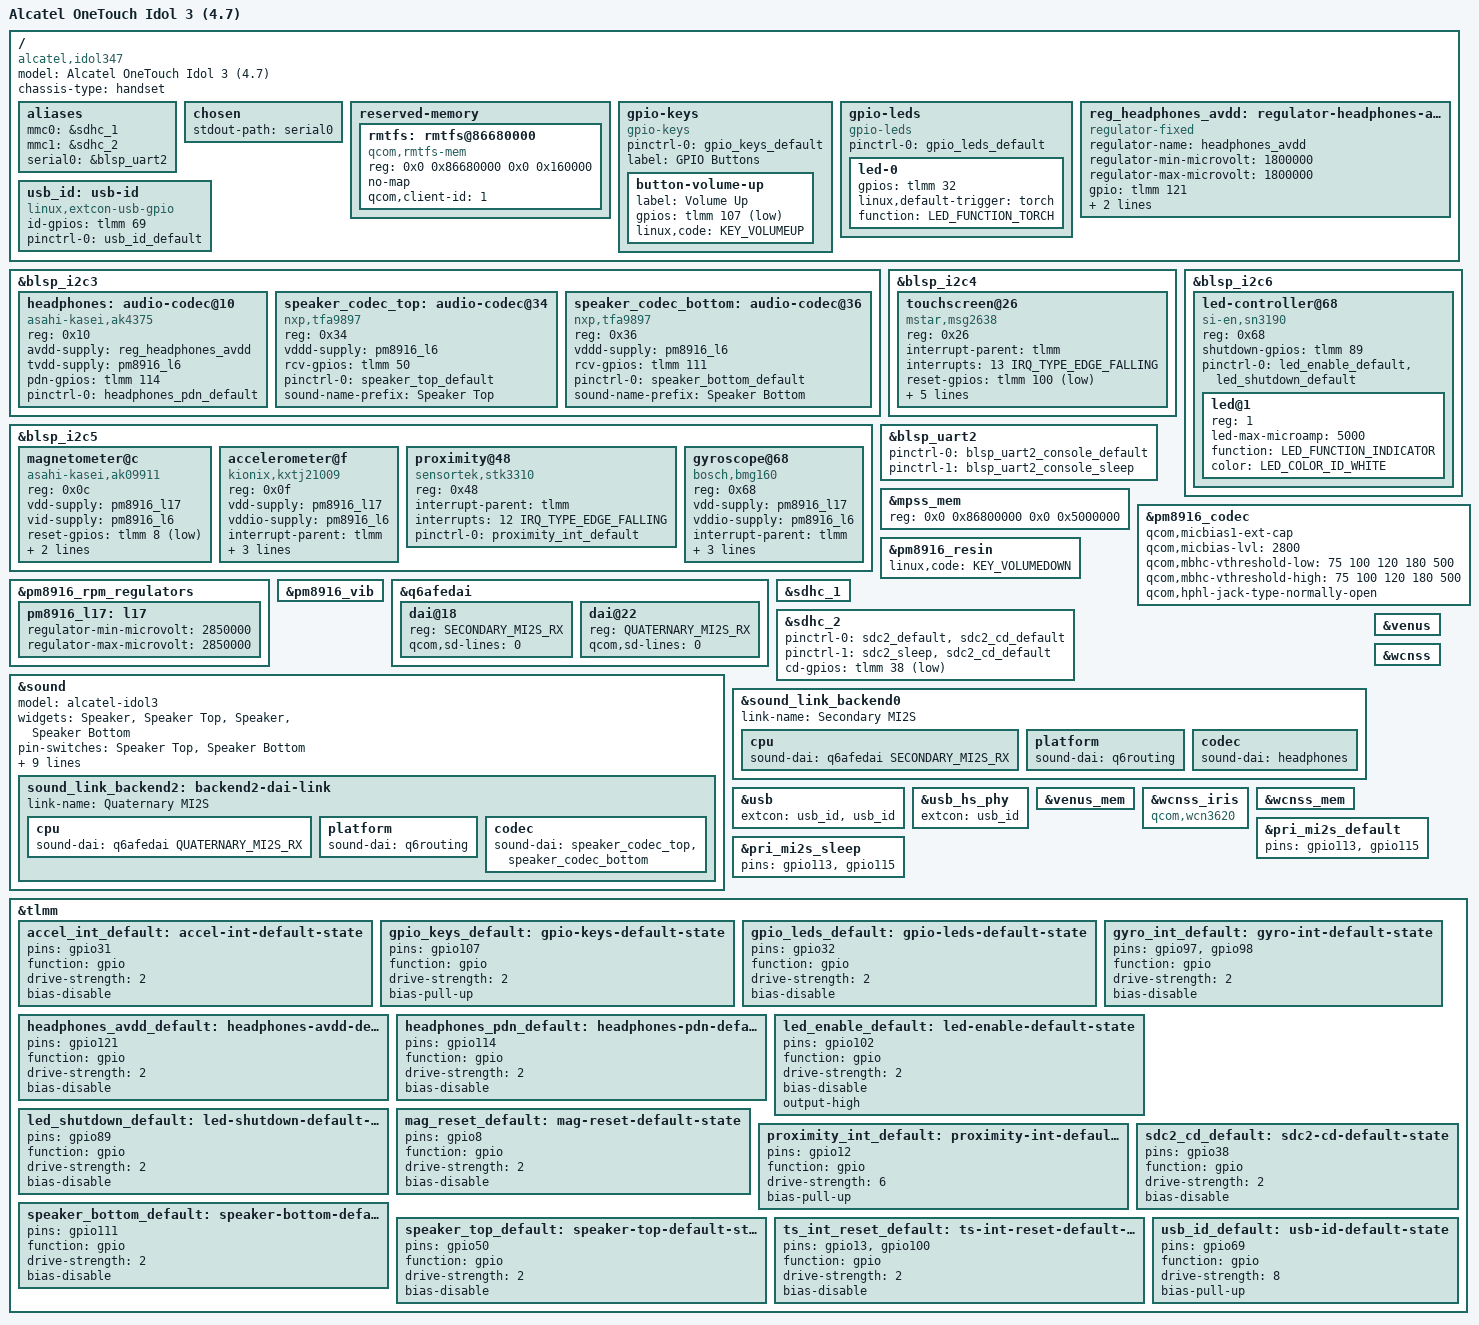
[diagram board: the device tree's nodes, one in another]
// SPDX-License-Identifier: GPL-2.0-only

/dts-v1/;

#include "msm8916-pm8916.dtsi"
#include "msm8916-modem-qdsp6.dtsi"

#include <dt-bindings/gpio/gpio.h>
#include <dt-bindings/input/input.h>
#include <dt-bindings/leds/common.h>

/ {
	model = "Alcatel OneTouch Idol 3 (4.7)";
	compatible = "alcatel,idol347", "qcom,msm8916";
	chassis-type = "handset";

	aliases {
		mmc0 = &sdhc_1; /* eMMC */
		mmc1 = &sdhc_2; /* SD card */
		serial0 = &blsp_uart2;
	};

	chosen {
		stdout-path = "serial0";
	};

	reserved-memory {
		/delete-node/ reserved@86680000;
		/delete-node/ rmtfs@86700000;

		rmtfs: rmtfs@86680000 {
			compatible = "qcom,rmtfs-mem";
			reg = <0x0 0x86680000 0x0 0x160000>;
			no-map;

			qcom,client-id = <1>;
		};
	};

	gpio-keys {
		compatible = "gpio-keys";

		pinctrl-names = "default";
		pinctrl-0 = <&gpio_keys_default>;

		label = "GPIO Buttons";

		button-volume-up {
			label = "Volume Up";
			gpios = <&tlmm 107 GPIO_ACTIVE_LOW>;
			linux,code = <KEY_VOLUMEUP>;
		};
	};

	gpio-leds {
		compatible = "gpio-leds";

		pinctrl-names = "default";
		pinctrl-0 = <&gpio_leds_default>;

		led-0 {
			gpios = <&tlmm 32 GPIO_ACTIVE_HIGH>;
			linux,default-trigger = "torch";
			function = LED_FUNCTION_TORCH;
		};
	};

	reg_headphones_avdd: regulator-headphones-avdd {
		compatible = "regulator-fixed";
		regulator-name = "headphones_avdd";
		regulator-min-microvolt = <1800000>;
		regulator-max-microvolt = <1800000>;
		gpio = <&tlmm 121 GPIO_ACTIVE_HIGH>;
		enable-active-high;
		pinctrl-0 = <&headphones_avdd_default>;
		pinctrl-names = "default";
	};

	usb_id: usb-id {
		compatible = "linux,extcon-usb-gpio";
		id-gpios = <&tlmm 69 GPIO_ACTIVE_HIGH>;
		pinctrl-names = "default";
		pinctrl-0 = <&usb_id_default>;
	};
};

&blsp_i2c3 {
	status = "okay";

	headphones: audio-codec@10 {
		compatible = "asahi-kasei,ak4375";
		reg = <0x10>;
		avdd-supply = <&reg_headphones_avdd>;
		tvdd-supply = <&pm8916_l6>;
		pdn-gpios = <&tlmm 114 GPIO_ACTIVE_HIGH>;
		pinctrl-0 = <&headphones_pdn_default>;
		pinctrl-names = "default";
		#sound-dai-cells = <0>;
	};

	speaker_codec_top: audio-codec@34 {
		compatible = "nxp,tfa9897";
		reg = <0x34>;
		vddd-supply = <&pm8916_l6>;
		rcv-gpios = <&tlmm 50 GPIO_ACTIVE_HIGH>;
		pinctrl-0 = <&speaker_top_default>;
		pinctrl-names = "default";
		sound-name-prefix = "Speaker Top";
		#sound-dai-cells = <0>;
	};

	speaker_codec_bottom: audio-codec@36 {
		compatible = "nxp,tfa9897";
		reg = <0x36>;
		vddd-supply = <&pm8916_l6>;
		rcv-gpios = <&tlmm 111 GPIO_ACTIVE_HIGH>;
		pinctrl-0 = <&speaker_bottom_default>;
		pinctrl-names = "default";
		sound-name-prefix = "Speaker Bottom";
		#sound-dai-cells = <0>;
	};
};

&blsp_i2c4 {
	status = "okay";

	touchscreen@26 {
		compatible = "mstar,msg2638";
		reg = <0x26>;
		interrupt-parent = <&tlmm>;
		interrupts = <13 IRQ_TYPE_EDGE_FALLING>;
		reset-gpios = <&tlmm 100 GPIO_ACTIVE_LOW>;
		pinctrl-names = "default";
		pinctrl-0 = <&ts_int_reset_default>;
		vdd-supply = <&pm8916_l17>;
		vddio-supply = <&pm8916_l5>;
		touchscreen-size-x = <2048>;
		touchscreen-size-y = <2048>;
	};
};

&blsp_i2c5 {
	status = "okay";

	magnetometer@c {
		compatible = "asahi-kasei,ak09911";
		reg = <0x0c>;
		vdd-supply = <&pm8916_l17>;
		vid-supply = <&pm8916_l6>;
		reset-gpios = <&tlmm 8 GPIO_ACTIVE_LOW>;
		pinctrl-names = "default";
		pinctrl-0 = <&mag_reset_default>;
		mount-matrix = "0", "1", "0",
			       "-1", "0", "0",
			       "0", "0", "1";
	};

	accelerometer@f {
		compatible = "kionix,kxtj21009";
		reg = <0x0f>;
		vdd-supply = <&pm8916_l17>;
		vddio-supply = <&pm8916_l6>;
		interrupt-parent = <&tlmm>;
		interrupts = <31 IRQ_TYPE_EDGE_RISING>;
		pinctrl-names = "default";
		pinctrl-0 = <&accel_int_default>;
		mount-matrix = "-1", "0", "0",
			       "0", "1", "0",
			       "0", "0", "-1";
	};

	proximity@48 {
		compatible = "sensortek,stk3310";
		reg = <0x48>;
		interrupt-parent = <&tlmm>;
		interrupts = <12 IRQ_TYPE_EDGE_FALLING>;
		pinctrl-names = "default";
		pinctrl-0 = <&proximity_int_default>;
	};

	gyroscope@68 {
		compatible = "bosch,bmg160";
		reg = <0x68>;
		vdd-supply = <&pm8916_l17>;
		vddio-supply = <&pm8916_l6>;
		interrupt-parent = <&tlmm>;
		interrupts = <97 IRQ_TYPE_EDGE_RISING>,
			     <98 IRQ_TYPE_EDGE_RISING>;
		pinctrl-names = "default";
		pinctrl-0 = <&gyro_int_default>;
	};
};

&blsp_i2c6 {
	status = "okay";

	led-controller@68 {
		compatible = "si-en,sn3190";
		reg = <0x68>;
		shutdown-gpios = <&tlmm 89 GPIO_ACTIVE_HIGH>;
		pinctrl-names = "default";
		pinctrl-0 = <&led_enable_default &led_shutdown_default>;
		#address-cells = <1>;
		#size-cells = <0>;

		led@1 {
			reg = <1>;
			led-max-microamp = <5000>;
			function = LED_FUNCTION_INDICATOR;
			color = <LED_COLOR_ID_WHITE>;
		};
	};
};

&blsp_uart2 {
	status = "okay";
	pinctrl-0 = <&blsp_uart2_console_default>;
	pinctrl-1 = <&blsp_uart2_console_sleep>;
	pinctrl-names = "default", "sleep";
};

&mpss_mem {
	reg = <0x0 0x86800000 0x0 0x5000000>;
};

&pm8916_codec {
	qcom,micbias1-ext-cap;
	qcom,micbias-lvl = <2800>;
	qcom,mbhc-vthreshold-low = <75 100 120 180 500>;
	qcom,mbhc-vthreshold-high = <75 100 120 180 500>;
	qcom,hphl-jack-type-normally-open;
};

&pm8916_resin {
	status = "okay";
	linux,code = <KEY_VOLUMEDOWN>;
};

&pm8916_rpm_regulators {
	pm8916_l17: l17 {
		regulator-min-microvolt = <2850000>;
		regulator-max-microvolt = <2850000>;
	};
};

&pm8916_vib {
	status = "okay";
};

&q6afedai {
	dai@18 {
		reg = <SECONDARY_MI2S_RX>;
		qcom,sd-lines = <0>;
	};
	dai@22 {
		reg = <QUATERNARY_MI2S_RX>;
		qcom,sd-lines = <0>;
	};
};

&sdhc_1 {
	status = "okay";
};

&sdhc_2 {
	status = "okay";

	pinctrl-names = "default", "sleep";
	pinctrl-0 = <&sdc2_default &sdc2_cd_default>;
	pinctrl-1 = <&sdc2_sleep &sdc2_cd_default>;

	cd-gpios = <&tlmm 38 GPIO_ACTIVE_LOW>;
};

&sound {
	/* Add pin switches for speakers to allow disabling them individually */
	model = "alcatel-idol3";
	widgets =
		"Speaker", "Speaker Top",
		"Speaker", "Speaker Bottom";
	pin-switches = "Speaker Top", "Speaker Bottom";
	audio-routing =
		"Speaker Top", "Speaker Top OUT",
		"Speaker Bottom", "Speaker Bottom OUT",
		"AMIC1", "MIC BIAS External1",
		"AMIC2", "MIC BIAS Internal2",
		"AMIC3", "MIC BIAS External1";

	pinctrl-0 = <&cdc_pdm_default &pri_mi2s_default &pri_mi2s_ws_default &sec_mi2s_default>;
	pinctrl-1 = <&cdc_pdm_sleep &pri_mi2s_sleep &pri_mi2s_ws_sleep &sec_mi2s_sleep>;
	pinctrl-names = "default", "sleep";

	sound_link_backend2: backend2-dai-link {
		link-name = "Quaternary MI2S";

		cpu {
			sound-dai = <&q6afedai QUATERNARY_MI2S_RX>;
		};
		platform {
			sound-dai = <&q6routing>;
		};
		codec {
			sound-dai = <&speaker_codec_top>, <&speaker_codec_bottom>;
		};
	};
};

&sound_link_backend0 {
	/* Primary MI2S is not used, replace with Secondary MI2S for headphones */
	link-name = "Secondary MI2S";

	cpu {
		sound-dai = <&q6afedai SECONDARY_MI2S_RX>;
	};
	platform {
		sound-dai = <&q6routing>;
	};
	codec {
		sound-dai = <&headphones>;
	};
};

&usb {
	status = "okay";
	extcon = <&usb_id>, <&usb_id>;
};

&usb_hs_phy {
	extcon = <&usb_id>;
};

&venus {
	status = "okay";
};

&venus_mem {
	status = "okay";
};

&wcnss {
	status = "okay";
};

&wcnss_iris {
	compatible = "qcom,wcn3620";
};

&wcnss_mem {
	status = "okay";
};

/* Only some of the pins are used */
&pri_mi2s_default {
	pins = "gpio113", "gpio115";
};

&pri_mi2s_sleep {
	pins = "gpio113", "gpio115";
};

&tlmm {
	accel_int_default: accel-int-default-state {
		pins = "gpio31";
		function = "gpio";

		drive-strength = <2>;
		bias-disable;
	};

	gpio_keys_default: gpio-keys-default-state {
		pins = "gpio107";
		function = "gpio";

		drive-strength = <2>;
		bias-pull-up;
	};

	gpio_leds_default: gpio-leds-default-state {
		pins = "gpio32";
		function = "gpio";

		drive-strength = <2>;
		bias-disable;
	};

	gyro_int_default: gyro-int-default-state {
		pins = "gpio97", "gpio98";
		function = "gpio";

		drive-strength = <2>;
		bias-disable;
	};

	headphones_avdd_default: headphones-avdd-default-state {
		pins = "gpio121";
		function = "gpio";
		drive-strength = <2>;
		bias-disable;
	};

	headphones_pdn_default: headphones-pdn-default-state {
		pins = "gpio114";
		function = "gpio";
		drive-strength = <2>;
		bias-disable;
	};

	/*
	 * The OEM wired an additional GPIO to be asserted so that
	 * the si-en,sn3190 LED IC works. Since this GPIO is not
	 * part of the IC datasheet nor supported by the driver,
	 * force it asserted here.
	 */
	led_enable_default: led-enable-default-state {
		pins = "gpio102";
		function = "gpio";

		drive-strength = <2>;
		bias-disable;
		output-high;
	};

	led_shutdown_default: led-shutdown-default-state {
		pins = "gpio89";
		function = "gpio";

		drive-strength = <2>;
		bias-disable;
	};

	mag_reset_default: mag-reset-default-state {
		pins = "gpio8";
		function = "gpio";

		drive-strength = <2>;
		bias-disable;
	};

	proximity_int_default: proximity-int-default-state {
		pins = "gpio12";
		function = "gpio";

		drive-strength = <6>;
		bias-pull-up;
	};

	sdc2_cd_default: sdc2-cd-default-state {
		pins = "gpio38";
		function = "gpio";
		drive-strength = <2>;
		bias-disable;
	};

	speaker_bottom_default: speaker-bottom-default-state {
		pins = "gpio111";
		function = "gpio";
		drive-strength = <2>;
		bias-disable;
	};

	speaker_top_default: speaker-top-default-state {
		pins = "gpio50";
		function = "gpio";
		drive-strength = <2>;
		bias-disable;
	};

	ts_int_reset_default: ts-int-reset-default-state {
		pins = "gpio13", "gpio100";
		function = "gpio";

		drive-strength = <2>;
		bias-disable;
	};

	usb_id_default: usb-id-default-state {
		pins = "gpio69";
		function = "gpio";

		drive-strength = <8>;
		bias-pull-up;
	};
};
